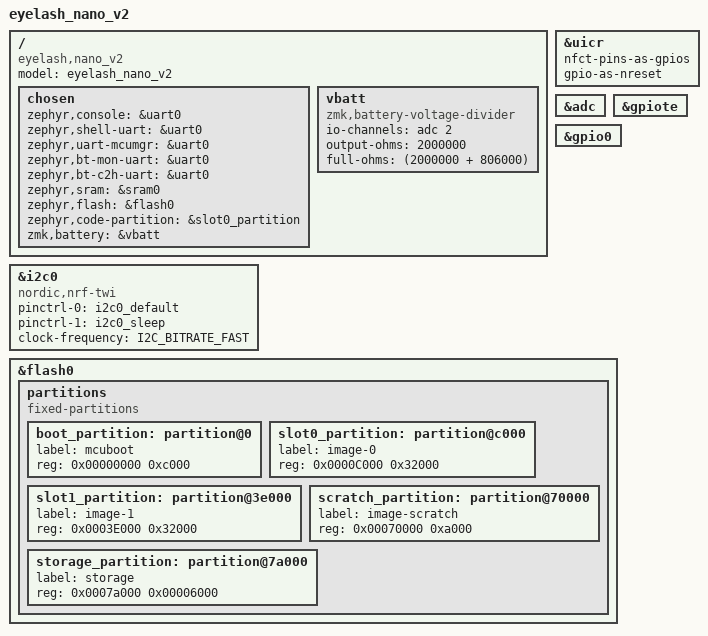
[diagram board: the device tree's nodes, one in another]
/*
 * Copyright (c) 2021 The ZMK Contributors
 *
 * SPDX-License-Identifier: MIT
 */
/dts-v1/;

#include <nordic/nrf52832_qfaa.dtsi>
#include "eyelash_nano_v2-pinctrl.dtsi"

/ {
    model = "eyelash_nano_v2";
    compatible = "eyelash,nano_v2";

    chosen {
        zephyr,console = &uart0;
		zephyr,shell-uart = &uart0;
		zephyr,uart-mcumgr = &uart0;
		zephyr,bt-mon-uart = &uart0;
		zephyr,bt-c2h-uart = &uart0;
		zephyr,sram = &sram0;
		zephyr,flash = &flash0;
        zephyr,code-partition = &slot0_partition;
        zmk,battery = &vbatt;
    };

    vbatt: vbatt {
        compatible = "zmk,battery-voltage-divider";
        io-channels = <&adc 2>;
        output-ohms = <2000000>;
        full-ohms = <(2000000 + 806000)>;
    };
};

&uicr {
    nfct-pins-as-gpios;
    gpio-as-nreset;
};

&adc {
	status ="okay";
};

&gpiote {
	status = "okay";
};

&gpio0 {
	status = "okay";
};

&i2c0 {
    compatible = "nordic,nrf-twi";
    pinctrl-0 = <&i2c0_default>;
    pinctrl-1 = <&i2c0_sleep>;
    pinctrl-names = "default", "sleep";
    clock-frequency = <I2C_BITRATE_FAST>;
};

&flash0 {
	/*
	 * For more information, see:
	 * http://docs.zephyrproject.org/latest/guides/dts/index.html#flash-partitions
	 */
	partitions {
		compatible = "fixed-partitions";
		#address-cells = <1>;
		#size-cells = <1>;

		boot_partition: partition@0 {
			label = "mcuboot";
			reg = <0x00000000 0xc000>;
		};
		slot0_partition: partition@c000 {
			label = "image-0";
			reg = <0x0000C000 0x32000>;
		};
		slot1_partition: partition@3e000 {
			label = "image-1";
			reg = <0x0003E000 0x32000>;
		};
		scratch_partition: partition@70000 {
			label = "image-scratch";
			reg = <0x00070000 0xa000>;
		};
		storage_partition: partition@7a000 {
			label = "storage";
			reg = <0x0007a000 0x00006000>;
		};
	};
};
